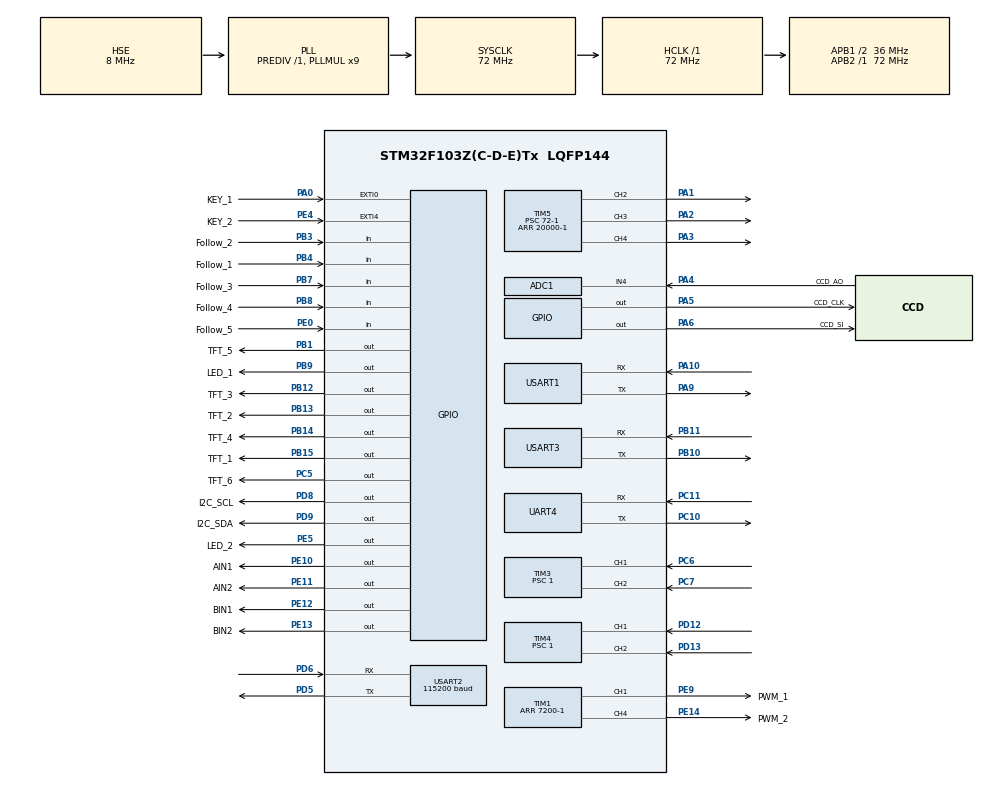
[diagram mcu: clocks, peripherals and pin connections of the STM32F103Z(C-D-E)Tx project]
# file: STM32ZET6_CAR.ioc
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ADC1.Channel-3\#ChannelRegularConversion=ADC_CHANNEL_4
ADC1.NbrOfConversionFlag=1
ADC1.Rank-3\#ChannelRegularConversion=1
ADC1.SamplingTime-3\#ChannelRegularConversion=ADC_SAMPLETIME_1CYCLE_5
ADC1.master=1
Mcu.Family=STM32F1
Mcu.Name=STM32F103Z(C-D-E)Tx
Mcu.Package=LQFP144
NVIC.EXTI0_IRQn=true\:1\:0\:true\:false\:true\:true\:true\:true
NVIC.EXTI4_IRQn=true\:1\:0\:true\:false\:true\:true\:true\:true
NVIC.PriorityGroup=NVIC_PRIORITYGROUP_4
NVIC.TIM2_IRQn=true\:0\:0\:false\:false\:true\:true\:true\:true
NVIC.UART4_IRQn=true\:0\:0\:false\:false\:true\:true\:true\:true
NVIC.USART1_IRQn=true\:0\:0\:false\:false\:true\:true\:true\:true
NVIC.USART2_IRQn=true\:0\:0\:false\:false\:true\:true\:true\:true
NVIC.USART3_IRQn=true\:0\:0\:false\:false\:true\:true\:true\:true
OSC_IN.Mode=HSE-External-Oscillator
OSC_IN.Signal=RCC_OSC_IN
OSC_OUT.Mode=HSE-External-Oscillator
OSC_OUT.Signal=RCC_OSC_OUT
PA0-WKUP.GPIO_Label=KEY_1
PA0-WKUP.GPIO_ModeDefaultEXTI=GPIO_MODE_IT_RISING
PA0-WKUP.GPIO_PuPd=GPIO_PULLDOWN
PA0-WKUP.Signal=GPXTI0
PA1.Signal=S_TIM5_CH2
PA10.Mode=Asynchronous
PA10.Signal=USART1_RX
PA13.Mode=Serial_Wire
PA13.Signal=SYS_JTMS-SWDIO
PA14.Mode=Serial_Wire
PA14.Signal=SYS_JTCK-SWCLK
PA2.Signal=S_TIM5_CH3
PA3.Signal=S_TIM5_CH4
PA4.GPIO_Label=CCD_AO
PA4.Signal=ADCx_IN4
PA5.GPIO_Label=CCD_CLK
PA5.Signal=GPIO_Output
PA6.GPIO_Label=CCD_SI
PA6.Signal=GPIO_Output
PA9.Mode=Asynchronous
PA9.Signal=USART1_TX
PB1.GPIO_Label=TFT_5
PB1.Signal=GPIO_Output
PB10.Mode=Asynchronous
PB10.Signal=USART3_TX
PB11.Mode=Asynchronous
PB11.Signal=USART3_RX
PB12.GPIO_Label=TFT_3
PB12.GPIO_ModeDefaultOutputPP=GPIO_MODE_OUTPUT_OD
PB12.GPIO_PuPd=GPIO_NOPULL
PB12.GPIO_Speed=GPIO_SPEED_FREQ_HIGH
PB12.Signal=GPIO_Output
PB13.GPIO_Label=TFT_2
PB13.GPIO_ModeDefaultOutputPP=GPIO_MODE_OUTPUT_OD
PB13.GPIO_PuPd=GPIO_NOPULL
PB13.GPIO_Speed=GPIO_SPEED_FREQ_HIGH
PB13.Signal=GPIO_Output
PB14.GPIO_Label=TFT_4
PB14.GPIO_ModeDefaultOutputPP=GPIO_MODE_OUTPUT_OD
PB14.GPIO_PuPd=GPIO_NOPULL
PB14.GPIO_Speed=GPIO_SPEED_FREQ_HIGH
PB14.Signal=GPIO_Output
PB15.GPIO_Label=TFT_1
PB15.GPIO_ModeDefaultOutputPP=GPIO_MODE_OUTPUT_OD
PB15.GPIO_PuPd=GPIO_NOPULL
PB15.GPIO_Speed=GPIO_SPEED_FREQ_HIGH
PB15.Signal=GPIO_Output
PB3.GPIO_Label=Follow_2
PB3.Signal=GPIO_Input
PB4.GPIO_Label=Follow_1
PB4.Signal=GPIO_Input
PB7.GPIO_Label=Follow_3
PB7.Signal=GPIO_Input
PB8.GPIO_Label=Follow_4
PB8.Signal=GPIO_Input
PB9.GPIO_Label=LED_1
PB9.Signal=GPIO_Output
PC10.Mode=Asynchronous
PC10.Signal=UART4_TX
PC11.Mode=Asynchronous
PC11.Signal=UART4_RX
PC5.GPIO_Label=TFT_6
PC5.GPIO_ModeDefaultOutputPP=GPIO_MODE_OUTPUT_OD
PC5.GPIO_PuPd=GPIO_NOPULL
PC5.GPIO_Speed=GPIO_SPEED_FREQ_HIGH
PC5.Signal=GPIO_Output
PC6.GPIO_PuPd=GPIO_NOPULL
PC6.Signal=S_TIM3_CH1
PC7.GPIO_PuPd=GPIO_NOPULL
PC7.Signal=S_TIM3_CH2
PD12.GPIO_PuPd=GPIO_NOPULL
PD12.Signal=S_TIM4_CH1
PD13.GPIO_PuPd=GPIO_NOPULL
PD13.Signal=S_TIM4_CH2
PD5.Mode=Asynchronous
PD5.Signal=USART2_TX
PD6.Mode=Asynchronous
PD6.Signal=USART2_RX
PD8.GPIO_Label=I2C_SCL
PD8.GPIO_ModeDefaultOutputPP=GPIO_MODE_OUTPUT_OD
PD8.GPIO_PuPd=GPIO_PULLUP
PD8.GPIO_Speed=GPIO_SPEED_FREQ_HIGH
PD8.Signal=GPIO_Output
PD9.GPIO_Label=I2C_SDA
PD9.GPIO_ModeDefaultOutputPP=GPIO_MODE_OUTPUT_OD
PD9.GPIO_PuPd=GPIO_PULLUP
PD9.GPIO_Speed=GPIO_SPEED_FREQ_HIGH
PD9.Signal=GPIO_Output
PE0.GPIO_Label=Follow_5
PE0.Signal=GPIO_Input
PE10.GPIO_Label=AIN1
PE10.Signal=GPIO_Output
PE11.GPIO_Label=AIN2
PE11.Signal=GPIO_Output
PE12.GPIO_Label=BIN1
PE12.Signal=GPIO_Output
PE13.GPIO_Label=BIN2
PE13.Signal=GPIO_Output
PE14.GPIO_Label=PWM_2
PE14.Signal=S_TIM1_CH4
PE4.GPIO_Label=KEY_2
PE4.GPIO_ModeDefaultEXTI=GPIO_MODE_IT_RISING
PE4.GPIO_PuPd=GPIO_PULLUP
PE4.Signal=GPXTI4
PE5.GPIO_Label=LED_2
PE5.Signal=GPIO_Output
PE9.GPIO_Label=PWM_1
PE9.Signal=S_TIM1_CH1
ProjectManager.HeapSize=0x200
ProjectManager.StackSize=0x400
ProjectManager.TargetToolchain=MDK-ARM V5.32
RCC.ADCPresc=RCC_ADCPCLK2_DIV6
RCC.AHBFreq_Value=72000000
RCC.APB1CLKDivider=RCC_HCLK_DIV2
RCC.APB1Freq_Value=36000000
RCC.APB1TimFreq_Value=72000000
RCC.APB2Freq_Value=72000000
RCC.APB2TimFreq_Value=72000000
RCC.HCLKFreq_Value=72000000
RCC.PLLMUL=RCC_PLL_MUL9
RCC.PLLSourceVirtual=RCC_PLLSOURCE_HSE
RCC.SYSCLKFreq_VALUE=72000000
RCC.SYSCLKSource=RCC_SYSCLKSOURCE_PLLCLK
RCC.USBFreq_Value=72000000
SH.ADCx_IN4.0=ADC1_IN4,IN4
SH.S_TIM1_CH1.0=TIM1_CH1,PWM Generation1 CH1
SH.S_TIM1_CH4.0=TIM1_CH4,PWM Generation4 CH4
SH.S_TIM3_CH1.0=TIM3_CH1,Encoder_Interface
SH.S_TIM3_CH2.0=TIM3_CH2,Encoder_Interface
SH.S_TIM4_CH1.0=TIM4_CH1,Encoder_Interface
SH.S_TIM4_CH2.0=TIM4_CH2,Encoder_Interface
SH.S_TIM5_CH2.0=TIM5_CH2,PWM Generation2 CH2
SH.S_TIM5_CH3.0=TIM5_CH3,PWM Generation3 CH3
SH.S_TIM5_CH4.0=TIM5_CH4,PWM Generation4 CH4
TIM1.AutoReloadPreload=TIM_AUTORELOAD_PRELOAD_ENABLE
TIM1.Channel-PWM\ Generation1\ CH1=TIM_CHANNEL_1
TIM1.Channel-PWM\ Generation4\ CH4=TIM_CHANNEL_4
TIM1.Period=7200-1
TIM2.AutoReloadPreload=TIM_AUTORELOAD_PRELOAD_ENABLE
TIM2.Period=1000-1
TIM2.Prescaler=72-1
TIM3.AutoReloadPreload=TIM_AUTORELOAD_PRELOAD_ENABLE
TIM3.EncoderMode=TIM_ENCODERMODE_TI12
TIM3.Prescaler=1
TIM4.AutoReloadPreload=TIM_AUTORELOAD_PRELOAD_ENABLE
TIM4.EncoderMode=TIM_ENCODERMODE_TI12
TIM4.Prescaler=1
TIM5.AutoReloadPreload=TIM_AUTORELOAD_PRELOAD_ENABLE
TIM5.Channel-PWM\ Generation2\ CH2=TIM_CHANNEL_2
TIM5.Channel-PWM\ Generation3\ CH3=TIM_CHANNEL_3
TIM5.Channel-PWM\ Generation4\ CH4=TIM_CHANNEL_4
TIM5.Period=20000-1
TIM5.Prescaler=72-1
UART4.VirtualMode=Asynchronous
USART1.VirtualMode=VM_ASYNC
USART2.BaudRate=115200
USART2.VirtualMode=VM_ASYNC
USART3.VirtualMode=VM_ASYNC
VP_TIM1_VS_ClockSourceINT.Mode=Internal
VP_TIM2_VS_ClockSourceINT.Mode=Internal
VP_TIM5_VS_ClockSourceINT.Mode=Internal
board=custom

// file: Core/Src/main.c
/* USER CODE BEGIN Header */
/**
  ******************************************************************************
  * @file           : main.c
  * @brief          : Main program body
  ******************************************************************************
  * @attention
  *
  * Copyright (c) 2023 STMicroelectronics.
  * All rights reserved.
  *
  * This software is licensed under terms that can be found in the LICENSE file
  * in the root directory of this software component.
  * If no LICENSE file comes with this software, it is provided AS-IS.
  *
  ******************************************************************************
  */
/* USER CODE END Header */
#include "main.h"
#include "adc.h"
#include "tim.h"
#include "usart.h"
#include "gpio.h"

/* USER CODE BEGIN Includes */
#include "app.h"
/* USER CODE END Includes */

void SystemClock_Config(void);

int main(void)
{

  /* MCU Configuration--------------------------------------------------------*/

  /* Reset of all peripherals, Initializes the Flash interface and the Systick. */
  HAL_Init();

  /* Configure the system clock */
  SystemClock_Config();

  /* Initialize all configured peripherals */
  MX_GPIO_Init();
  MX_TIM1_Init();
  MX_TIM2_Init();
  MX_TIM3_Init();
  MX_TIM4_Init();
  MX_USART1_UART_Init();
  MX_USART2_UART_Init();
  MX_USART3_UART_Init();
  MX_UART4_Init();
  MX_TIM5_Init();
  MX_ADC1_Init();
  /* USER CODE BEGIN 2 */
  //应用
  App_Init();
  /* USER CODE END 2 */

  /* Infinite loop */
  while (1)
  {

    /* USER CODE BEGIN 3 */
    App_Task();
  }
  /* USER CODE END 3 */
}

void SystemClock_Config(void)
{
  RCC_OscInitTypeDef RCC_OscInitStruct = {0};
  RCC_ClkInitTypeDef RCC_ClkInitStruct = {0};
  RCC_PeriphCLKInitTypeDef PeriphClkInit = {0};

  /** Initializes the RCC Oscillators according to the specified parameters
  * in the RCC_OscInitTypeDef structure.
  */
  RCC_OscInitStruct.OscillatorType = RCC_OSCILLATORTYPE_HSE;
  RCC_OscInitStruct.HSEState = RCC_HSE_ON;
  RCC_OscInitStruct.HSEPredivValue = RCC_HSE_PREDIV_DIV1;
  RCC_OscInitStruct.HSIState = RCC_HSI_ON;
  RCC_OscInitStruct.PLL.PLLState = RCC_PLL_ON;
  RCC_OscInitStruct.PLL.PLLSource = RCC_PLLSOURCE_HSE;
  RCC_OscInitStruct.PLL.PLLMUL = RCC_PLL_MUL9;
  if (HAL_RCC_OscConfig(&RCC_OscInitStruct) != HAL_OK)
  {
    Error_Handler();
  }

  /** Initializes the CPU, AHB and APB buses clocks
  */
  RCC_ClkInitStruct.ClockType = RCC_CLOCKTYPE_HCLK|RCC_CLOCKTYPE_SYSCLK
                              |RCC_CLOCKTYPE_PCLK1|RCC_CLOCKTYPE_PCLK2;
  RCC_ClkInitStruct.SYSCLKSource = RCC_SYSCLKSOURCE_PLLCLK;
  RCC_ClkInitStruct.AHBCLKDivider = RCC_SYSCLK_DIV1;
  RCC_ClkInitStruct.APB1CLKDivider = RCC_HCLK_DIV2;
  RCC_ClkInitStruct.APB2CLKDivider = RCC_HCLK_DIV1;

  if (HAL_RCC_ClockConfig(&RCC_ClkInitStruct, FLASH_LATENCY_2) != HAL_OK)
  {
    Error_Handler();
  }
  PeriphClkInit.PeriphClockSelection = RCC_PERIPHCLK_ADC;
  PeriphClkInit.AdcClockSelection = RCC_ADCPCLK2_DIV6;
  if (HAL_RCCEx_PeriphCLKConfig(&PeriphClkInit) != HAL_OK)
  {
    Error_Handler();
  }
}

void Error_Handler(void)
{
  __disable_irq();
  while (1)
  {
  }
}
